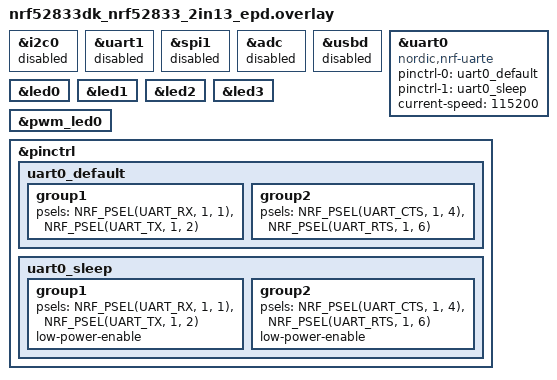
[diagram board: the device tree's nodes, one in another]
#include "waveshare_epaper_HINK-E0213-G01.dtsi"

&i2c0 {
	status = "disabled";
};
&uart1 {
	status = "disabled";
};
&spi1 {
	status = "disabled";
};
&adc {
	status = "disabled";
};
&usbd {
	status = "disabled";
};

// Zephyr Console and FTDI Port
&uart0 {
	pinctrl-0 = <&uart0_default>;
	pinctrl-1 = <&uart0_sleep>;
	pinctrl-names = "default", "sleep";
	compatible = "nordic,nrf-uarte";
	current-speed = <115200>;
};

&led0 {
	status="okay";
};

&led1 {
	status="okay";
};

&led2 {
	status="okay";
};

&led3 {
	status="okay";
};

&pwm_led0 {
	status="okay";
};


&pinctrl {
	uart0_default: uart0_default {
		group1 {
			psels = <NRF_PSEL(UART_RX, 1, 1)>, 
				<NRF_PSEL(UART_TX, 1, 2)>;     
		};
		group2 {
			psels = <NRF_PSEL(UART_CTS, 1, 4)>, 
				<NRF_PSEL(UART_RTS, 1, 6)>;     
		};
	};

	uart0_sleep: uart0_sleep {
		group1 {
			psels = <NRF_PSEL(UART_RX, 1, 1)>, 
				<NRF_PSEL(UART_TX, 1, 2)>;	   
			low-power-enable;
		};
		group2 {
			psels = <NRF_PSEL(UART_CTS, 1, 4)>, 
				<NRF_PSEL(UART_RTS, 1, 6)>;	   
			low-power-enable;
		};
	};
};
